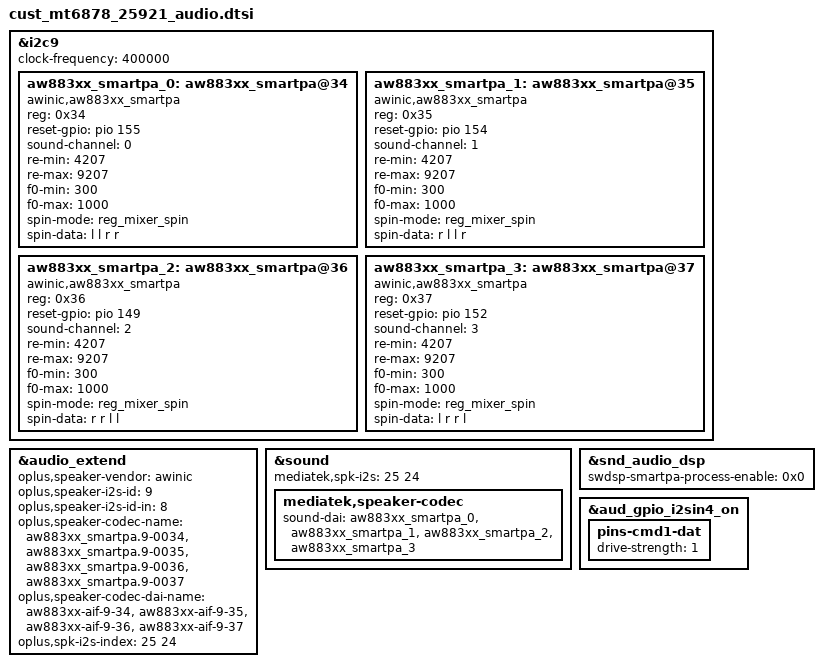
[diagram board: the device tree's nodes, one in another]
// SPDX-License-Identifier: GPL-2.0
/* Copyright (c) 2020 MediaTek Inc. */

&i2c9 {
	clock-frequency = <400000>;

	aw883xx_smartpa_0: aw883xx_smartpa@34 {
		compatible = "awinic,aw883xx_smartpa";
		#sound-dai-cells = <0>;
		reg = <0x34>;
		reset-gpio = <&pio 155 0>;
		sound-channel = <0>;
		re-min = <4207>;
		re-max= <9207>;
		f0-min = <300>;
		f0-max= <1000>;
		spin-mode = "reg_mixer_spin";
		spin-data = "l l r r";
		status = "okay";
	};

	aw883xx_smartpa_1: aw883xx_smartpa@35 {
		compatible = "awinic,aw883xx_smartpa";
		#sound-dai-cells = <0>;
		reg = <0x35>;
		reset-gpio = <&pio 154 0>;
		sound-channel = <1>;
		re-min = <4207>;
		re-max= <9207>;
		f0-min = <300>;
		f0-max= <1000>;
		spin-mode = "reg_mixer_spin";
		spin-data = "r l l r";
		status = "okay";
	};

	aw883xx_smartpa_2: aw883xx_smartpa@36 {
		compatible = "awinic,aw883xx_smartpa";
		#sound-dai-cells = <0>;
		reg = <0x36>;
		reset-gpio = <&pio 149 0>;
		sound-channel = <2>;
		re-min = <4207>;
		re-max= <9207>;
		f0-min = <300>;
		f0-max= <1000>;
		spin-mode = "reg_mixer_spin";
		spin-data = "r r l l";
		status = "okay";
	};

	aw883xx_smartpa_3: aw883xx_smartpa@37 {
		compatible = "awinic,aw883xx_smartpa";
		#sound-dai-cells = <0>;
		reg = <0x37>;
		reset-gpio = <&pio 152 0>;
		sound-channel = <3>;
		re-min = <4207>;
		re-max= <9207>;
		f0-min = <300>;
		f0-max= <1000>;
		spin-mode = "reg_mixer_spin";
		spin-data = "l r r l";
		status = "okay";
	};
};

&audio_extend {
	//for awinic speaker
	oplus,speaker-vendor = "awinic";
	oplus,speaker-i2s-id = <9>;
	oplus,speaker-i2s-id-in = <8>;
	oplus,speaker-codec-name = "aw883xx_smartpa.9-0034","aw883xx_smartpa.9-0035","aw883xx_smartpa.9-0036","aw883xx_smartpa.9-0037";
	oplus,speaker-codec-dai-name = "aw883xx-aif-9-34","aw883xx-aif-9-35","aw883xx-aif-9-36","aw883xx-aif-9-37";
	oplus,spk-i2s-index = <25 24>;
	status = "okay";
};

&sound {
	mediatek,spk-i2s = <25 24>;
	mediatek,speaker-codec {
		sound-dai = <&aw883xx_smartpa_0 &aw883xx_smartpa_1 &aw883xx_smartpa_2 &aw883xx_smartpa_3>;
	};
};

&snd_audio_dsp {
	swdsp-smartpa-process-enable = <0x0>;
};

&aud_gpio_i2sin4_on {
	pins-cmd1-dat {
		drive-strength = <1>;
	};

};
